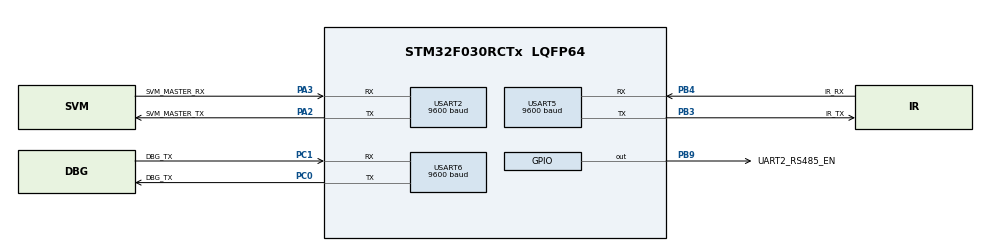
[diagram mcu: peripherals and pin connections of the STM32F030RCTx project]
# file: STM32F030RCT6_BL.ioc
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Mcu.Family=STM32F0
Mcu.Name=STM32F030RCTx
Mcu.Package=LQFP64
NVIC.FLASH_IRQn=true\:0\:0\:false\:false\:true\:true\:true
NVIC.RCC_IRQn=true\:0\:0\:false\:false\:true\:true\:false
NVIC.USART2_IRQn=true\:0\:0\:false\:true\:true\:2\:true\:true
NVIC.USART3_6_IRQn=true\:0\:0\:false\:true\:true\:1\:true\:true
PA2.GPIO_Label=SVM_MASTER_TX
PA2.Mode=Asynchronous
PA2.Signal=USART2_TX
PA3.GPIO_Label=SVM_MASTER_RX
PA3.Mode=Asynchronous
PA3.Signal=USART2_RX
PB3.GPIO_Label=IR_TX
PB3.Mode=Asynchronous
PB3.Signal=USART5_TX
PB4.GPIO_Label=IR_RX
PB4.Mode=Asynchronous
PB4.Signal=USART5_RX
PB9.GPIO_Label=UART2_RS485_EN
PB9.Signal=GPIO_Output
PC0.GPIO_Label=DBG_TX
PC0.Mode=Asynchronous
PC0.Signal=USART6_TX
PC1.GPIO_Label=DBG_TX
PC1.Mode=Asynchronous
PC1.Signal=USART6_RX
ProjectManager.HeapSize=0x200
ProjectManager.StackSize=0x400
ProjectManager.TargetToolchain=STM32CubeIDE
USART2.BaudRate=9600
USART2.VirtualMode-Asynchronous=VM_ASYNC
USART5.BaudRate=9600
USART5.VirtualMode-Asynchronous=VM_ASYNC
USART6.BaudRate=9600
USART6.VirtualMode=VM_ASYNC
VP_CRC_VS_CRC.Mode=CRC_Activate
board=custom

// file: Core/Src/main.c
/* USER CODE BEGIN Header */
/**
  ******************************************************************************
  * @file           : main.c
  * @brief          : Main program body
  ******************************************************************************
  * @attention
  *
  * <h2><center>&copy; Copyright (c) 2020 STMicroelectronics.
  * All rights reserved.</center></h2>
  *
  * This software component is licensed by ST under BSD 3-Clause license,
  * the "License"; You may not use this file except in compliance with the
  * License. You may obtain a copy of the License at:
  *                        opensource.org/licenses/BSD-3-Clause
  *
  ******************************************************************************
  */
/* USER CODE END Header */
#include "main.h"

/* USER CODE BEGIN Includes */
#include "Bootloader.h"
#include "Ldrprotocol.h"
/* USER CODE END Includes */

CRC_HandleTypeDef hcrc;

UART_HandleTypeDef huart2;
UART_HandleTypeDef huart5;
UART_HandleTypeDef huart6;

void SystemClock_Config(void);
static void MX_GPIO_Init(void);
static void MX_USART5_UART_Init(void);
static void MX_USART6_UART_Init(void);
static void MX_CRC_Init(void);
static void MX_USART2_UART_Init(void);
static void MX_NVIC_Init(void);

int main(void)
{

  /* MCU Configuration--------------------------------------------------------*/

  /* Reset of all peripherals, Initializes the Flash interface and the Systick. */
  HAL_Init();

  /* Configure the system clock */
  SystemClock_Config();

  /* Initialize all configured peripherals */
  MX_GPIO_Init();
  MX_USART5_UART_Init();
  MX_USART6_UART_Init();
  MX_CRC_Init();
  MX_USART2_UART_Init();

  /* Initialize interrupts */
  MX_NVIC_Init();
  /* USER CODE BEGIN 2 */

  STM32_Serial_PutString("CLO-V1.0\r\n");

  //Required Memory Allocated
  Initialize_Parameter();

  //Bootloader Main Process
  BL_PROCESS();

  STM32_Serial_PutString("\r\n<<<<--Catastrophic  Failure-->>>>\r\n");
  STM32_Serial_PutString("\r\n<<<<--Inform To Developer-->>>>\r\n");
  /* USER CODE END 2 */

  /* Infinite loop */
  /* USER CODE BEGIN WHILE */
  while (1)
  {
	  HAL_Delay(2000);
    /* USER CODE END WHILE */

  }
}

void SystemClock_Config(void)
{
  RCC_OscInitTypeDef RCC_OscInitStruct = {0};
  RCC_ClkInitTypeDef RCC_ClkInitStruct = {0};

  /** Initializes the RCC Oscillators according to the specified parameters
  * in the RCC_OscInitTypeDef structure.
  */
  RCC_OscInitStruct.OscillatorType = RCC_OSCILLATORTYPE_HSI;
  RCC_OscInitStruct.HSIState = RCC_HSI_ON;
  RCC_OscInitStruct.HSICalibrationValue = RCC_HSICALIBRATION_DEFAULT;
  RCC_OscInitStruct.PLL.PLLState = RCC_PLL_NONE;
  if (HAL_RCC_OscConfig(&RCC_OscInitStruct) != HAL_OK)
  {
    Error_Handler();
  }
  /** Initializes the CPU, AHB and APB buses clocks
  */
  RCC_ClkInitStruct.ClockType = RCC_CLOCKTYPE_HCLK|RCC_CLOCKTYPE_SYSCLK
                              |RCC_CLOCKTYPE_PCLK1;
  RCC_ClkInitStruct.SYSCLKSource = RCC_SYSCLKSOURCE_HSI;
  RCC_ClkInitStruct.AHBCLKDivider = RCC_SYSCLK_DIV1;
  RCC_ClkInitStruct.APB1CLKDivider = RCC_HCLK_DIV1;

  if (HAL_RCC_ClockConfig(&RCC_ClkInitStruct, FLASH_LATENCY_0) != HAL_OK)
  {
    Error_Handler();
  }
}

/**
  * @brief NVIC Configuration.
  * @retval None
  */
static void MX_NVIC_Init(void)
{
  /* USART3_6_IRQn interrupt configuration */
  HAL_NVIC_SetPriority(USART3_6_IRQn, 0, 0);
  HAL_NVIC_EnableIRQ(USART3_6_IRQn);
  /* USART2_IRQn interrupt configuration */
  HAL_NVIC_SetPriority(USART2_IRQn, 0, 0);
  HAL_NVIC_EnableIRQ(USART2_IRQn);
}

static void MX_CRC_Init(void)
{

  hcrc.Instance = CRC;
  hcrc.Init.DefaultInitValueUse = DEFAULT_INIT_VALUE_ENABLE;
  hcrc.Init.InputDataInversionMode = CRC_INPUTDATA_INVERSION_NONE;
  hcrc.Init.OutputDataInversionMode = CRC_OUTPUTDATA_INVERSION_DISABLE;
  hcrc.InputDataFormat = CRC_INPUTDATA_FORMAT_BYTES;
  if (HAL_CRC_Init(&hcrc) != HAL_OK)
  {
    Error_Handler();
  }

}

static void MX_USART2_UART_Init(void)
{

  huart2.Instance = USART2;
  huart2.Init.BaudRate = 9600;
  huart2.Init.WordLength = UART_WORDLENGTH_8B;
  huart2.Init.StopBits = UART_STOPBITS_1;
  huart2.Init.Parity = UART_PARITY_NONE;
  huart2.Init.Mode = UART_MODE_TX_RX;
  huart2.Init.HwFlowCtl = UART_HWCONTROL_NONE;
  huart2.Init.OverSampling = UART_OVERSAMPLING_16;
  huart2.Init.OneBitSampling = UART_ONE_BIT_SAMPLE_DISABLE;
  huart2.AdvancedInit.AdvFeatureInit = UART_ADVFEATURE_NO_INIT;
  if (HAL_UART_Init(&huart2) != HAL_OK)
  {
    Error_Handler();
  }

}

static void MX_USART5_UART_Init(void)
{

  huart5.Instance = USART5;
  huart5.Init.BaudRate = 9600;
  huart5.Init.WordLength = UART_WORDLENGTH_8B;
  huart5.Init.StopBits = UART_STOPBITS_1;
  huart5.Init.Parity = UART_PARITY_NONE;
  huart5.Init.Mode = UART_MODE_TX_RX;
  huart5.Init.HwFlowCtl = UART_HWCONTROL_NONE;
  huart5.Init.OverSampling = UART_OVERSAMPLING_16;
  huart5.Init.OneBitSampling = UART_ONE_BIT_SAMPLE_DISABLE;
  huart5.AdvancedInit.AdvFeatureInit = UART_ADVFEATURE_NO_INIT;
  if (HAL_UART_Init(&huart5) != HAL_OK)
  {
    Error_Handler();
  }

}

static void MX_USART6_UART_Init(void)
{

  huart6.Instance = USART6;
  huart6.Init.BaudRate = 9600;
  huart6.Init.WordLength = UART_WORDLENGTH_8B;
  huart6.Init.StopBits = UART_STOPBITS_1;
  huart6.Init.Parity = UART_PARITY_NONE;
  huart6.Init.Mode = UART_MODE_TX_RX;
  huart6.Init.HwFlowCtl = UART_HWCONTROL_NONE;
  huart6.Init.OverSampling = UART_OVERSAMPLING_16;
  huart6.Init.OneBitSampling = UART_ONE_BIT_SAMPLE_DISABLE;
  huart6.AdvancedInit.AdvFeatureInit = UART_ADVFEATURE_NO_INIT;
  if (HAL_UART_Init(&huart6) != HAL_OK)
  {
    Error_Handler();
  }

}

static void MX_GPIO_Init(void)
{
  GPIO_InitTypeDef GPIO_InitStruct = {0};

  /* GPIO Ports Clock Enable */
  __HAL_RCC_GPIOC_CLK_ENABLE();
  __HAL_RCC_GPIOA_CLK_ENABLE();
  __HAL_RCC_GPIOB_CLK_ENABLE();

  /*Configure GPIO pin Output Level */
  HAL_GPIO_WritePin(UART2_RS485_EN_GPIO_Port, UART2_RS485_EN_Pin, GPIO_PIN_RESET);

  /*Configure GPIO pin : UART2_RS485_EN_Pin */
  GPIO_InitStruct.Pin = UART2_RS485_EN_Pin;
  GPIO_InitStruct.Mode = GPIO_MODE_OUTPUT_PP;
  GPIO_InitStruct.Pull = GPIO_NOPULL;
  GPIO_InitStruct.Speed = GPIO_SPEED_FREQ_LOW;
  HAL_GPIO_Init(UART2_RS485_EN_GPIO_Port, &GPIO_InitStruct);

}

void Error_Handler(void)
{
}

/************************ (C) COPYRIGHT STMicroelectronics *****END OF FILE****/
